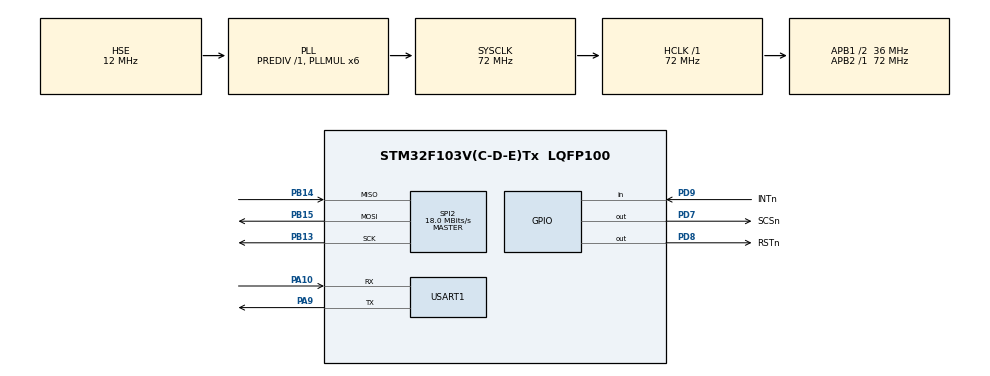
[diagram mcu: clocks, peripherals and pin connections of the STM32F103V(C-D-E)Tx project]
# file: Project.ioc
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Mcu.Family=STM32F1
Mcu.Name=STM32F103V(C-D-E)Tx
Mcu.Package=LQFP100
NVIC.PriorityGroup=NVIC_PRIORITYGROUP_4
NVIC.TIM2_IRQn=true\:0\:0\:false\:false\:true\:true\:true\:true
OSC_IN.Mode=HSE-External-Oscillator
OSC_IN.Signal=RCC_OSC_IN
OSC_OUT.Mode=HSE-External-Oscillator
OSC_OUT.Signal=RCC_OSC_OUT
PA10.Mode=Asynchronous
PA10.Signal=USART1_RX
PA9.Mode=Asynchronous
PA9.Signal=USART1_TX
PB13.Mode=Full_Duplex_Master
PB13.Signal=SPI2_SCK
PB14.Mode=Full_Duplex_Master
PB14.Signal=SPI2_MISO
PB15.Mode=Full_Duplex_Master
PB15.Signal=SPI2_MOSI
PD7.GPIO_Label=SCSn
PD7.GPIO_ModeDefaultOutputPP=GPIO_MODE_OUTPUT_OD
PD7.GPIO_PuPd=GPIO_PULLUP
PD7.GPIO_Speed=GPIO_SPEED_FREQ_HIGH
PD7.PinState=GPIO_PIN_SET
PD7.Signal=GPIO_Output
PD8.GPIO_Label=RSTn
PD8.GPIO_ModeDefaultOutputPP=GPIO_MODE_OUTPUT_OD
PD8.GPIO_PuPd=GPIO_PULLUP
PD8.GPIO_Speed=GPIO_SPEED_FREQ_HIGH
PD8.PinState=GPIO_PIN_SET
PD8.Signal=GPIO_Output
PD9.GPIO_Label=INTn
PD9.Signal=GPIO_Input
ProjectManager.HeapSize=0x400
ProjectManager.StackSize=0x800
ProjectManager.TargetToolchain=MDK-ARM V5.32
RCC.AHBFreq_Value=72000000
RCC.APB1CLKDivider=RCC_HCLK_DIV2
RCC.APB1Freq_Value=36000000
RCC.APB1TimFreq_Value=72000000
RCC.APB2Freq_Value=72000000
RCC.APB2TimFreq_Value=72000000
RCC.HCLKFreq_Value=72000000
RCC.HSE_VALUE=12000000
RCC.PLLMUL=RCC_PLL_MUL6
RCC.PLLSourceVirtual=RCC_PLLSOURCE_HSE
RCC.SYSCLKFreq_VALUE=72000000
RCC.SYSCLKSource=RCC_SYSCLKSOURCE_PLLCLK
RCC.USBFreq_Value=72000000
SPI2.BaudRatePrescaler=SPI_BAUDRATEPRESCALER_2
SPI2.CalculateBaudRate=18.0 MBits/s
SPI2.Direction=SPI_DIRECTION_2LINES
SPI2.Mode=SPI_MODE_MASTER
SPI2.VirtualType=VM_MASTER
TIM2.Period=1000-1
TIM2.Prescaler=72-1
USART1.VirtualMode=VM_ASYNC
VP_SYS_VS_ND.Mode=No_Debug
VP_TIM2_VS_ClockSourceINT.Mode=Internal
board=custom

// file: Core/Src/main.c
/* USER CODE BEGIN Header */
/**
 ******************************************************************************
 * @file           : main.c
 * @brief          : Main program body
 ******************************************************************************
 * @attention
 *
 * Copyright (c) 2024 STMicroelectronics.
 * All rights reserved.
 *
 * This software is licensed under terms that can be found in the LICENSE file
 * in the root directory of this software component.
 * If no LICENSE file comes with this software, it is provided AS-IS.
 *
 ******************************************************************************
 */

/* USER CODE END Header */
#include "main.h"
#include "spi.h"
#include "tim.h"
#include "usart.h"
#include "gpio.h"

/* USER CODE BEGIN Includes */
#include "user_main.h"

/* USER CODE END Includes */

/* USER CODE BEGIN PM */
/* network information */

/* USER CODE END PM */

void SystemClock_Config(void);

int main(void)
{

  /* MCU Configuration--------------------------------------------------------*/

  /* Reset of all peripherals, Initializes the Flash interface and the Systick. */
  HAL_Init();

  /* Configure the system clock */
  SystemClock_Config();

  /* Initialize all configured peripherals */
  MX_GPIO_Init();
  MX_USART1_UART_Init();
  MX_SPI2_Init();
  MX_TIM2_Init();
  /* USER CODE BEGIN 2 */
	user_run();
  /* USER CODE END 2 */

  /* Infinite loop */
  while (1)
  {

  }
}

void SystemClock_Config(void)
{
  RCC_OscInitTypeDef RCC_OscInitStruct = {0};
  RCC_ClkInitTypeDef RCC_ClkInitStruct = {0};

  /** Initializes the RCC Oscillators according to the specified parameters
  * in the RCC_OscInitTypeDef structure.
  */
  RCC_OscInitStruct.OscillatorType = RCC_OSCILLATORTYPE_HSE;
  RCC_OscInitStruct.HSEState = RCC_HSE_ON;
  RCC_OscInitStruct.HSEPredivValue = RCC_HSE_PREDIV_DIV1;
  RCC_OscInitStruct.HSIState = RCC_HSI_ON;
  RCC_OscInitStruct.PLL.PLLState = RCC_PLL_ON;
  RCC_OscInitStruct.PLL.PLLSource = RCC_PLLSOURCE_HSE;
  RCC_OscInitStruct.PLL.PLLMUL = RCC_PLL_MUL6;
  if (HAL_RCC_OscConfig(&RCC_OscInitStruct) != HAL_OK)
  {
    Error_Handler();
  }

  /** Initializes the CPU, AHB and APB buses clocks
  */
  RCC_ClkInitStruct.ClockType = RCC_CLOCKTYPE_HCLK|RCC_CLOCKTYPE_SYSCLK
                              |RCC_CLOCKTYPE_PCLK1|RCC_CLOCKTYPE_PCLK2;
  RCC_ClkInitStruct.SYSCLKSource = RCC_SYSCLKSOURCE_PLLCLK;
  RCC_ClkInitStruct.AHBCLKDivider = RCC_SYSCLK_DIV1;
  RCC_ClkInitStruct.APB1CLKDivider = RCC_HCLK_DIV2;
  RCC_ClkInitStruct.APB2CLKDivider = RCC_HCLK_DIV1;

  if (HAL_RCC_ClockConfig(&RCC_ClkInitStruct, FLASH_LATENCY_2) != HAL_OK)
  {
    Error_Handler();
  }
}

void Error_Handler(void)
{
  __disable_irq();
  while (1)
  {
  }
}
